# ioat91sam3s4 register map
Registers are 32-bit, access not given, no defined reset value unless marked. A register's access mark holds for its fields unless they carry their own. Addresses are absolute; registers are grouped by the start of their names; [hi:lo] are bit positions; {n}, {i} and the like mark numbered series; 'fields as' and 'values as' point back to an identical list.

## SPI
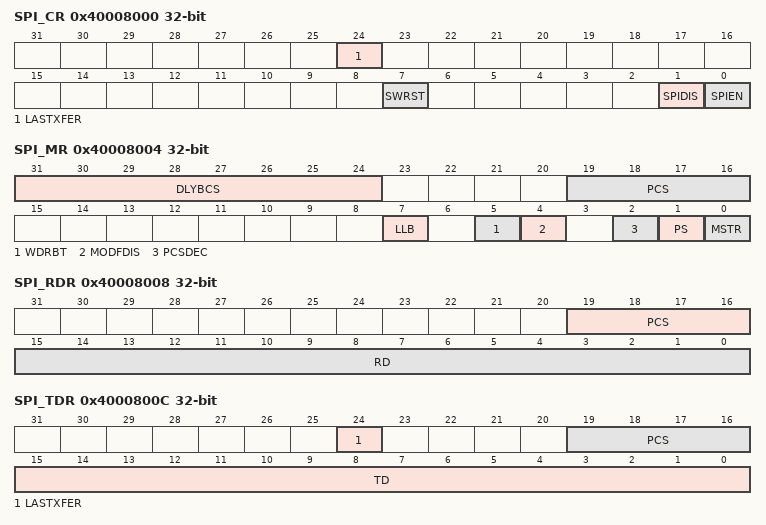
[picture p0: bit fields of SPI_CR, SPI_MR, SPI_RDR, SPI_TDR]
0x40008000 SPI_CR
  [24] LASTXFER, [7] SWRST, [1] SPIDIS, [0] SPIEN
0x40008004 SPI_MR
  [31:24] DLYBCS, [19:16] PCS, [7] LLB, [5] WDRBT, [4] MODFDIS, [2] PCSDEC, [1] PS, [0] MSTR
0x40008008 SPI_RDR
  [19:16] PCS, [15:0] RD
0x4000800C SPI_TDR
  [24] LASTXFER, [19:16] PCS, [15:0] TD
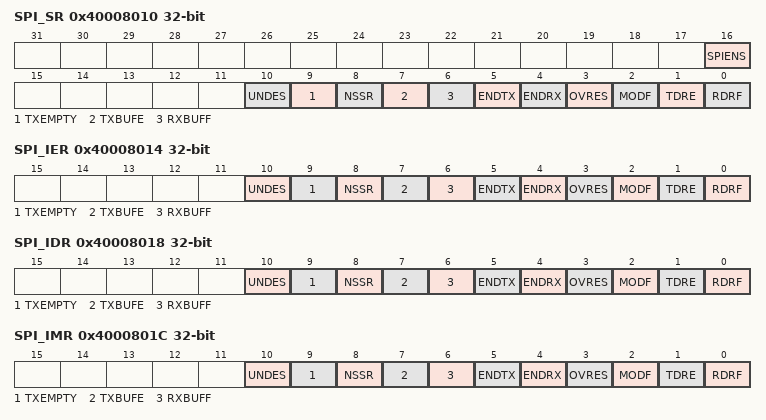
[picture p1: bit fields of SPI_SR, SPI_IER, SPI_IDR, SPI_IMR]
0x40008010 SPI_SR
  [16] SPIENS, [10] UNDES, [9] TXEMPTY, [8] NSSR, [7] TXBUFE, [6] RXBUFF, [5] ENDTX, [4] ENDRX, [3] OVRES, [2] MODF, [1] TDRE, [0] RDRF
0x40008014 SPI_IER
  [10] UNDES, [9] TXEMPTY, [8] NSSR, [7] TXBUFE, [6] RXBUFF, [5] ENDTX, [4] ENDRX, [3] OVRES, [2] MODF, [1] TDRE, [0] RDRF
0x40008018 SPI_IDR
  fields as SPI_IER
0x4000801C SPI_IMR
  fields as SPI_IER
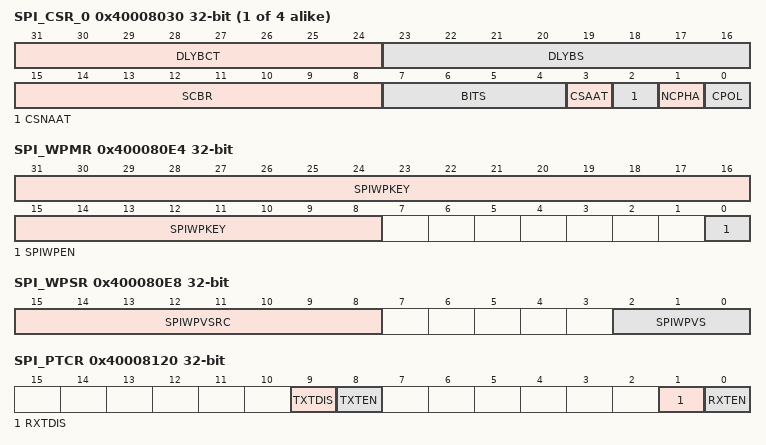
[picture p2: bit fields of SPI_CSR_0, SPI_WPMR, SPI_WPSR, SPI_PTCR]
0x40008030 SPI_CSR_{i} (i=0..3)
  [31:24] DLYBCT, [23:16] DLYBS, [15:8] SCBR, [7:4] BITS, [3] CSAAT, [2] CSNAAT, [1] NCPHA, [0] CPOL
0x400080E4 SPI_WPMR
  [31:8] SPIWPKEY, [0] SPIWPEN
0x400080E8 SPI_WPSR
  [15:8] SPIWPVSRC, [2:0] SPIWPVS
0x40008100 SPI_RPR
  [31:0] RXPTR
0x40008104 SPI_RCR
  [15:0] RXCTR
0x40008108 SPI_TPR
  [31:0] TXPTR
0x4000810C SPI_TCR
  [15:0] TXCTR
0x40008110 SPI_RNPR
  [31:0] RXNPTR
0x40008114 SPI_RNCR
  [15:0] RXNCTR
0x40008118 SPI_TNPR
  [31:0] TXNPTR
0x4000811C SPI_TNCR
  [15:0] TXNCTR
0x40008120 SPI_PTCR
  [9] TXTDIS, [8] TXTEN, [1] RXTDIS, [0] RXTEN
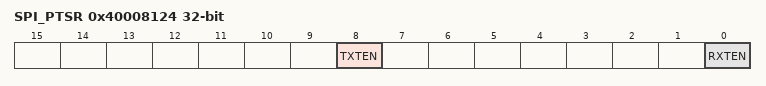
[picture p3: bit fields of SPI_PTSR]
0x40008124 SPI_PTSR
  [8] TXTEN, [0] RXTEN

## TC0
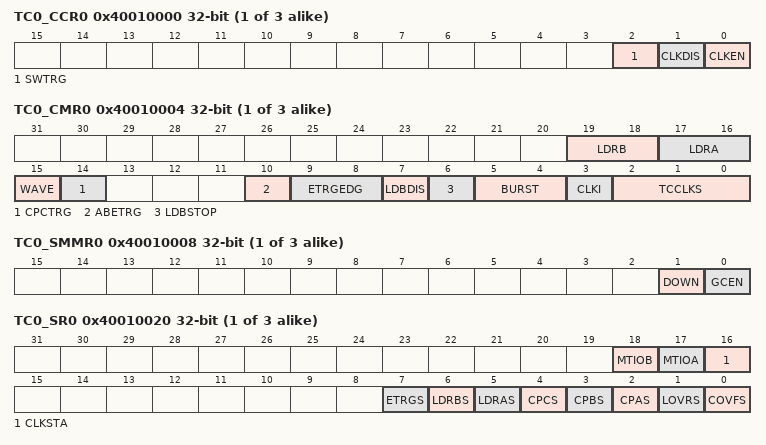
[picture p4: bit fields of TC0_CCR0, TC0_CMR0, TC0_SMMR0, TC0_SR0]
{0x40010000+0x40*i} TC0_CCR{i} (i=0..2)
  [2] SWTRG, [1] CLKDIS, [0] CLKEN
{0x40010004+0x40*i} TC0_CMR{i} (i=0..2)
  [19:18] LDRB, [17:16] LDRA, [15] WAVE, [14] CPCTRG, [10] ABETRG, [9:8] ETRGEDG, [7] LDBDIS, [6] LDBSTOP, [5:4] BURST, [3] CLKI, [2:0] TCCLKS
{0x40010008+0x40*i} TC0_SMMR{i} (i=0..2)
  [1] DOWN, [0] GCEN
{0x40010010+0x40*i} TC0_CV{i} (i=0..2)
  [15:0] CV
{0x40010014+0x40*i} TC0_RA{i} (i=0..2)
  [15:0] RA
{0x40010018+0x40*i} TC0_RB{i} (i=0..2)
  [15:0] RB
{0x4001001C+0x40*i} TC0_RC{i} (i=0..2)
  [15:0] RC
{0x40010020+0x40*i} TC0_SR{i} (i=0..2)
  [18] MTIOB, [17] MTIOA, [16] CLKSTA, [7] ETRGS, [6] LDRBS, [5] LDRAS, [4] CPCS, [3] CPBS, [2] CPAS, [1] LOVRS, [0] COVFS
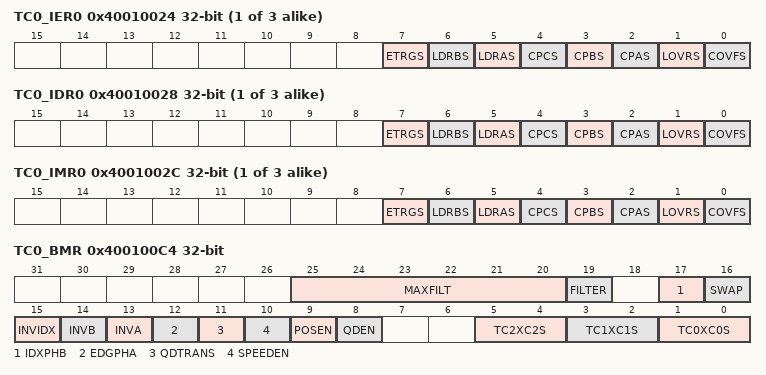
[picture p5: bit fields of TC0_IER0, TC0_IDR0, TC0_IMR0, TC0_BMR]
{0x40010024+0x40*i} TC0_IER{i} (i=0..2)
  [7] ETRGS, [6] LDRBS, [5] LDRAS, [4] CPCS, [3] CPBS, [2] CPAS, [1] LOVRS, [0] COVFS
{0x40010028+0x40*i} TC0_IDR{i} (i=0..2)
  fields as TC0_IER0
{0x4001002C+0x40*i} TC0_IMR{i} (i=0..2)
  fields as TC0_IER0
0x400100C0 TC0_BCR
  [0] SYNC
0x400100C4 TC0_BMR
  [25:20] MAXFILT, [19] FILTER, [17] IDXPHB, [16] SWAP, [15] INVIDX, [14] INVB, [13] INVA, [12] EDGPHA, [11] QDTRANS, [10] SPEEDEN, [9] POSEN, [8] QDEN, [5:4] TC2XC2S, [3:2] TC1XC1S, [1:0] TC0XC0S
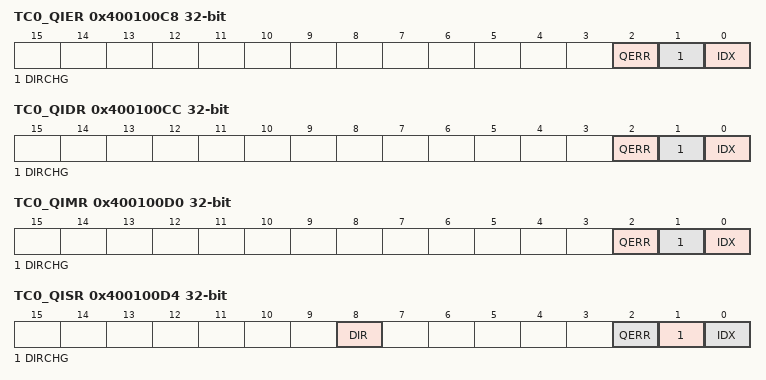
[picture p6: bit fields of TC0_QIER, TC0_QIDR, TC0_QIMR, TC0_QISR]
0x400100C8 TC0_QIER
  [2] QERR, [1] DIRCHG, [0] IDX
0x400100CC TC0_QIDR
  [2] QERR, [1] DIRCHG, [0] IDX
0x400100D0 TC0_QIMR
  [2] QERR, [1] DIRCHG, [0] IDX
0x400100D4 TC0_QISR
  [8] DIR, [2] QERR, [1] DIRCHG, [0] IDX
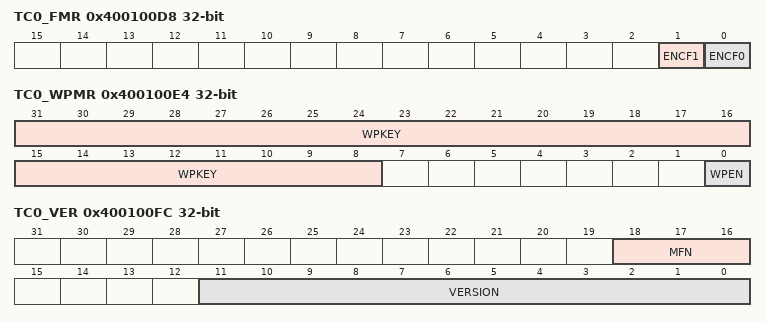
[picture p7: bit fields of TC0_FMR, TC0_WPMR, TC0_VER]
0x400100D8 TC0_FMR
  [1] ENCF1, [0] ENCF0
0x400100E4 TC0_WPMR
  [31:8] WPKEY, [0] WPEN
0x400100FC TC0_VER
  [18:16] MFN, [11:0] VERSION

## TC1
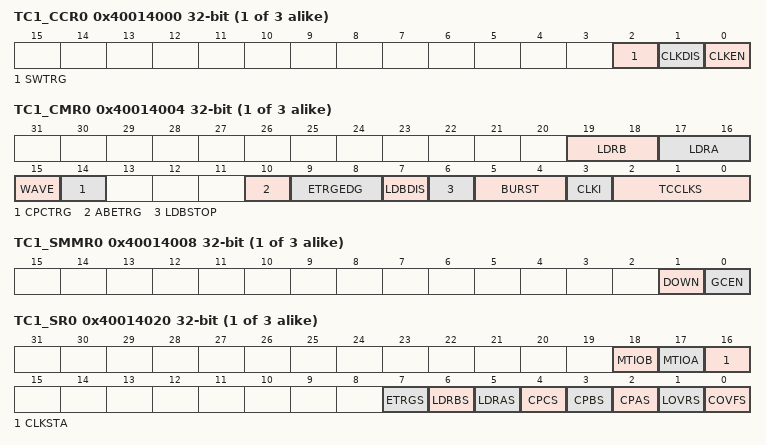
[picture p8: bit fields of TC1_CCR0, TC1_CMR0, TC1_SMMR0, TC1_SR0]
{0x40014000+0x40*i} TC1_CCR{i} (i=0..2)
  [2] SWTRG, [1] CLKDIS, [0] CLKEN
{0x40014004+0x40*i} TC1_CMR{i} (i=0..2)
  [19:18] LDRB, [17:16] LDRA, [15] WAVE, [14] CPCTRG, [10] ABETRG, [9:8] ETRGEDG, [7] LDBDIS, [6] LDBSTOP, [5:4] BURST, [3] CLKI, [2:0] TCCLKS
{0x40014008+0x40*i} TC1_SMMR{i} (i=0..2)
  [1] DOWN, [0] GCEN
{0x40014010+0x40*i} TC1_CV{i} (i=0..2)
  [15:0] CV
{0x40014014+0x40*i} TC1_RA{i} (i=0..2)
  [15:0] RA
{0x40014018+0x40*i} TC1_RB{i} (i=0..2)
  [15:0] RB
{0x4001401C+0x40*i} TC1_RC{i} (i=0..2)
  [15:0] RC
{0x40014020+0x40*i} TC1_SR{i} (i=0..2)
  [18] MTIOB, [17] MTIOA, [16] CLKSTA, [7] ETRGS, [6] LDRBS, [5] LDRAS, [4] CPCS, [3] CPBS, [2] CPAS, [1] LOVRS, [0] COVFS
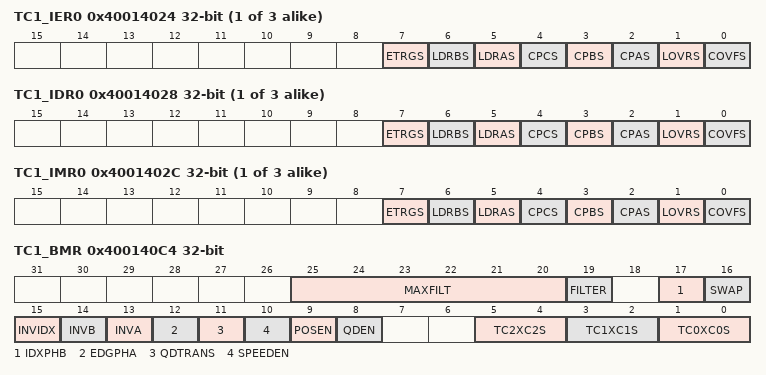
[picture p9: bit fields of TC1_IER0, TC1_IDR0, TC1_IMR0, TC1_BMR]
{0x40014024+0x40*i} TC1_IER{i} (i=0..2)
  [7] ETRGS, [6] LDRBS, [5] LDRAS, [4] CPCS, [3] CPBS, [2] CPAS, [1] LOVRS, [0] COVFS
{0x40014028+0x40*i} TC1_IDR{i} (i=0..2)
  fields as TC1_IER0
{0x4001402C+0x40*i} TC1_IMR{i} (i=0..2)
  fields as TC1_IER0
0x400140C0 TC1_BCR
  [0] SYNC
0x400140C4 TC1_BMR
  [25:20] MAXFILT, [19] FILTER, [17] IDXPHB, [16] SWAP, [15] INVIDX, [14] INVB, [13] INVA, [12] EDGPHA, [11] QDTRANS, [10] SPEEDEN, [9] POSEN, [8] QDEN, [5:4] TC2XC2S, [3:2] TC1XC1S, [1:0] TC0XC0S
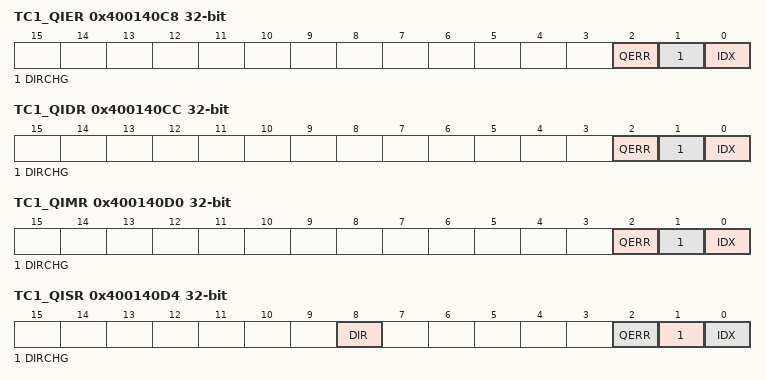
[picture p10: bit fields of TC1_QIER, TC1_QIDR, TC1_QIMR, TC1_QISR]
0x400140C8 TC1_QIER
  [2] QERR, [1] DIRCHG, [0] IDX
0x400140CC TC1_QIDR
  [2] QERR, [1] DIRCHG, [0] IDX
0x400140D0 TC1_QIMR
  [2] QERR, [1] DIRCHG, [0] IDX
0x400140D4 TC1_QISR
  [8] DIR, [2] QERR, [1] DIRCHG, [0] IDX
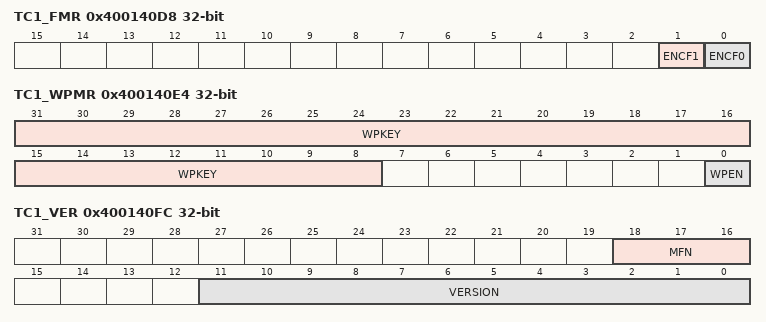
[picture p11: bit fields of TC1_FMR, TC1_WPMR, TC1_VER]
0x400140D8 TC1_FMR
  [1] ENCF1, [0] ENCF0
0x400140E4 TC1_WPMR
  [31:8] WPKEY, [0] WPEN
0x400140FC TC1_VER
  [18:16] MFN, [11:0] VERSION

## Notices in the file
Copyright (c) 2009, Atmel Corporation
All rights reserved.
Redistribution and use in source and binary forms, with or without
modification, are permitted provided that the following condition is met:
- Redistributions of source code must retain the above copyright notice,
this list of conditions and the disclaimer below.
Atmel's name may not be used to endorse or promote products derived from
this software without specific prior written permission.
DISCLAIMER:  THIS SOFTWARE IS PROVIDED BY ATMEL "AS IS" AND ANY EXPRESS OR
IMPLIED WARRANTIES, INCLUDING, BUT NOT LIMITED TO, THE IMPLIED WARRANTIES OF
MERCHANTABILITY, FITNESS FOR A PARTICULAR PURPOSE AND NON-INFRINGEMENT ARE
DISCLAIMED. IN NO EVENT SHALL ATMEL BE LIABLE FOR ANY DIRECT, INDIRECT,
INCIDENTAL, SPECIAL, EXEMPLARY, OR CONSEQUENTIAL DAMAGES (INCLUDING, BUT NOT
LIMITED TO, PROCUREMENT OF SUBSTITUTE GOODS OR SERVICES; LOSS OF USE, DATA,
OR PROFITS; OR BUSINESS INTERRUPTION) HOWEVER CAUSED AND ON ANY THEORY OF
LIABILITY, WHETHER IN CONTRACT, STRICT LIABILITY, OR TORT (INCLUDING
NEGLIGENCE OR OTHERWISE) ARISING IN ANY WAY OUT OF THE USE OF THIS SOFTWARE,
EVEN IF ADVISED OF THE POSSIBILITY OF SUCH DAMAGE.
